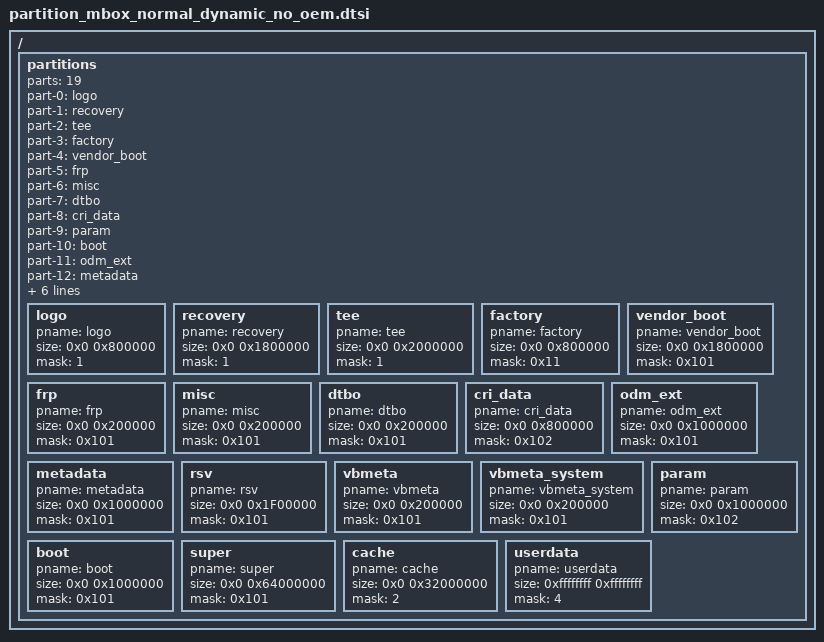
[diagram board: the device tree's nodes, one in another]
// SPDX-License-Identifier: (GPL-2.0+ OR MIT)
/*
 * Amlogic partition set for normal
 *
 * Copyright (c) 2017-2017 Amlogic Ltd
 *
 * This file is licensed under a dual GPLv2 or BSD license.
 *
 */

#include "firmware_avb_no_oem.dtsi"

/ {
    partitions: partitions{
		parts = <19>;
		part-0 = <&logo>;
		part-1 = <&recovery>;
		part-2 = <&tee>;
		part-3 = <&factory>;
		part-4 = <&vendor_boot>;
		part-5 = <&frp>;
		part-6 = <&misc>;
		part-7 = <&dtbo>;
		part-8 = <&cri_data>;
		part-9 = <&param>;
		part-10 = <&boot>;
		part-11 = <&odm_ext>;
		part-12 = <&metadata>;
		part-13 = <&rsv>;
		part-14 = <&vbmeta>;
		part-15 = <&vbmeta_system>;
		part-16 = <&super>;
		part-17 = <&cache>;
		part-18 = <&userdata>;

		logo:logo{
			pname = "logo";
			size = <0x0 0x800000>;
			mask = <1>;
		};
		recovery:recovery{
			pname = "recovery";
			size = <0x0 0x1800000>;
			mask = <1>;
		};
		tee:tee{
			pname = "tee";
			size = <0x0 0x2000000>;
			mask = <1>;
		};
		factory:factory{
			pname = "factory";
			size = <0x0 0x800000>;
			mask = <0x11>;
		};
		vendor_boot:vendor_boot{
			pname = "vendor_boot";
			size = <0x0 0x1800000>;
			mask = <0x101>;
		};
		frp:frp{
			pname = "frp";
			size = <0x0 0x200000>;
			mask = <0x101>;
		};
		misc:misc{
			pname = "misc";
			size = <0x0 0x200000>;
			mask = <0x101>;
		};
		dtbo:dtbo{
			pname = "dtbo";
			size = <0x0 0x200000>;
			mask = <0x101>;
		};
		cri_data:cri_data
		{
			pname = "cri_data";
			size = <0x0 0x800000>;
			mask = <0x102>;
		};
		odm_ext:odm_ext{
			pname = "odm_ext";
			size = <0x0 0x1000000>;
			mask = <0x101>;
		};
		metadata:metadata{
			pname = "metadata";
			size = <0x0 0x1000000>;
			mask = <0x101>;
		};
		rsv:rsv{
			pname = "rsv";
			size = <0x0 0x1F00000>;
			mask = <0x101>;
		};
		vbmeta:vbmeta{
			pname = "vbmeta";
			size = <0x0 0x200000>;
			mask = <0x101>;
		};
		vbmeta_system:vbmeta_system{
			pname = "vbmeta_system";
			size = <0x0 0x200000>;
			mask = <0x101>;
		};
		param:param{
			pname = "param";
			size = <0x0 0x1000000>;
			mask = <0x102>;
		};
		boot:boot
		{
			pname = "boot";
			size = <0x0 0x1000000>;
			mask = <0x101>;
		};
		super:super
		{
			pname = "super";
			size = <0x0 0x64000000>;
			mask = <0x101>;
		};
		cache:cache
		{
			pname = "cache";
			size = <0x0 0x32000000>;
			mask = <2>;
		};
		userdata:userdata
		{
			pname = "userdata";
			size = <0xffffffff 0xffffffff>;
			mask = <4>;
		};
	};
};/* end of / */
